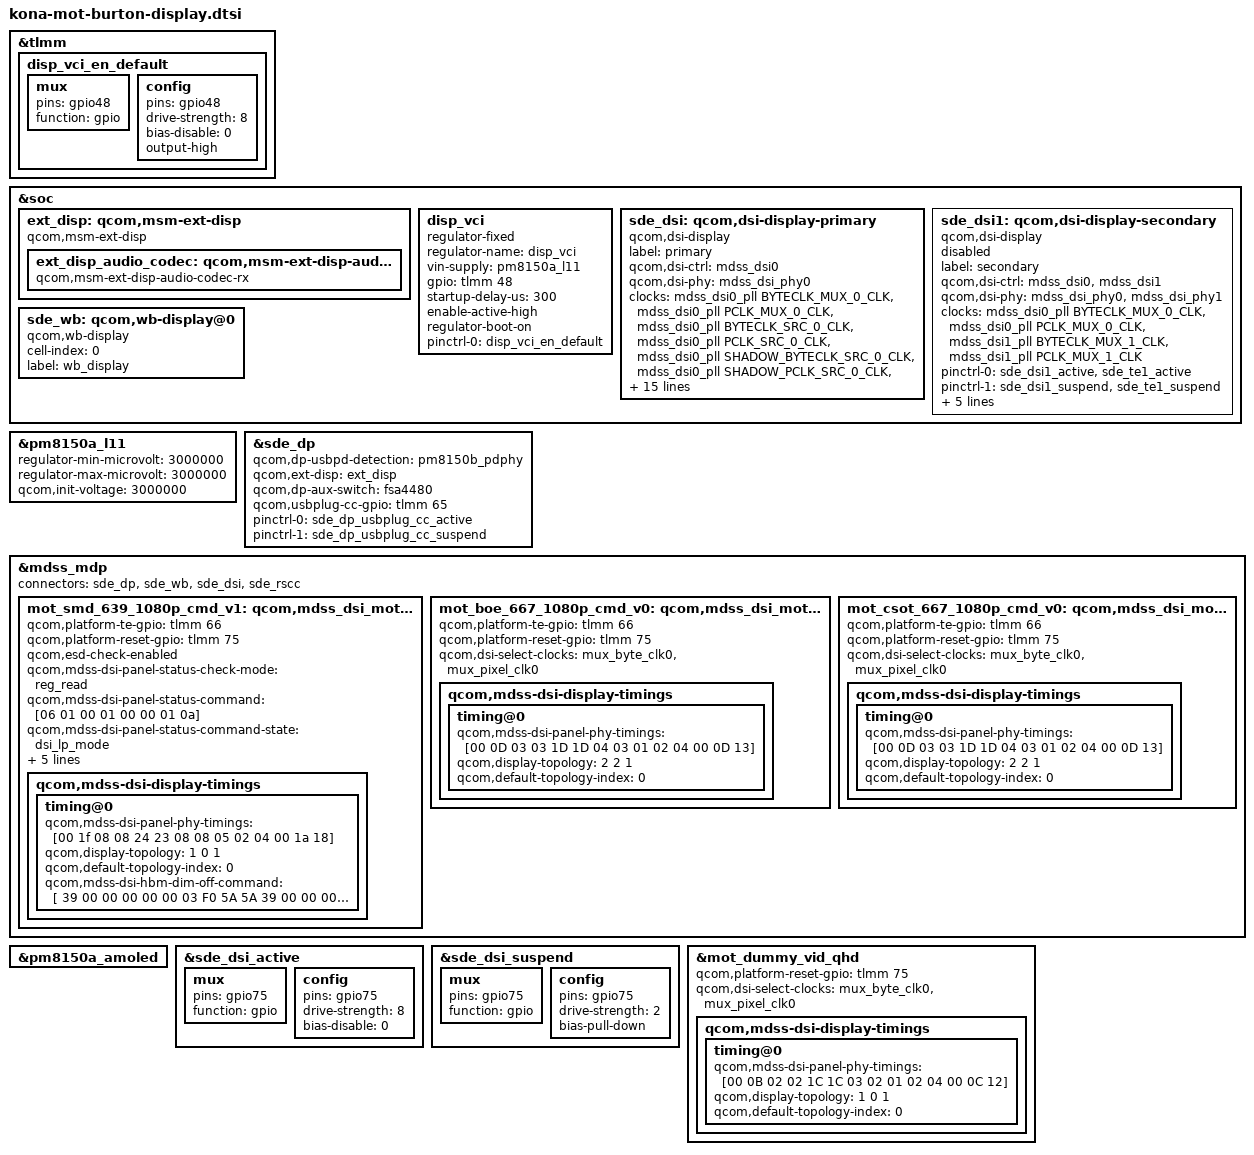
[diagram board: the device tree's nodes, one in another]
#include <dt-bindings/clock/mdss-7nm-pll-clk.h>
#include "dsi-panel-mot-dummy-qhd-video.dtsi"

&tlmm {
	disp_vci_en_default: disp_vci_en_default {
		mux {
			pins = "gpio48";
			function = "gpio";
		};

		config {
			pins = "gpio48";
			drive-strength = <8>;
			bias-disable = <0>;
			output-high;
		};
	};
};

&soc {
	ext_disp: qcom,msm-ext-disp {
		compatible = "qcom,msm-ext-disp";

		ext_disp_audio_codec: qcom,msm-ext-disp-audio-codec-rx {
			compatible = "qcom,msm-ext-disp-audio-codec-rx";
		};
	};


	disp_vci: disp_vci {
		compatible = "regulator-fixed";
		regulator-name = "disp_vci";
		vin-supply = <&pm8150a_l11>;
		gpio = <&tlmm 48 0>;
		startup-delay-us = <300>;
		enable-active-high;
		regulator-boot-on;
		pinctrl-names = "default";
		pinctrl-0 = <&disp_vci_en_default>;
	};

	sde_dsi: qcom,dsi-display-primary {
		compatible = "qcom,dsi-display";
		label = "primary";

		qcom,dsi-ctrl = <&mdss_dsi0>;
		qcom,dsi-phy = <&mdss_dsi_phy0>;


		clocks = <&mdss_dsi0_pll BYTECLK_MUX_0_CLK>,
			<&mdss_dsi0_pll PCLK_MUX_0_CLK>,
			<&mdss_dsi0_pll BYTECLK_SRC_0_CLK>,
			<&mdss_dsi0_pll PCLK_SRC_0_CLK>,
			<&mdss_dsi0_pll SHADOW_BYTECLK_SRC_0_CLK>,
			<&mdss_dsi0_pll SHADOW_PCLK_SRC_0_CLK>,
			<&mdss_dsi1_pll BYTECLK_MUX_1_CLK>,
			<&mdss_dsi1_pll PCLK_MUX_1_CLK>,
			<&mdss_dsi1_pll BYTECLK_SRC_1_CLK>,
			<&mdss_dsi1_pll PCLK_SRC_1_CLK>,
			<&mdss_dsi1_pll SHADOW_BYTECLK_SRC_1_CLK>,
			<&mdss_dsi1_pll SHADOW_PCLK_SRC_1_CLK>;

		clock-names = "mux_byte_clk0", "mux_pixel_clk0",
			"src_byte_clk0", "src_pixel_clk0",
			"shadow_byte_clk0", "shadow_pixel_clk0",
			"mux_byte_clk1", "mux_pixel_clk1",
			"src_byte_clk1", "src_pixel_clk1",
			"shadow_byte_clk1", "shadow_pixel_clk1";

		pinctrl-names = "panel_active", "panel_suspend";
		pinctrl-0 = <&sde_dsi_active &sde_te_active>;
		pinctrl-1 = <&sde_dsi_suspend &sde_te_suspend>;

		qcom,platform-te-gpio = <&tlmm 66 0>;
		qcom,panel-te-source = <0>;

		vddio-supply = <&pm8150_l14>;
		vci-supply = <&disp_vci>;
		qcom,dsi-default-panel = <&mot_boe_667_1080p_cmd_v0>;

		qcom,mdp = <&mdss_mdp>;
	};


	sde_dsi1: qcom,dsi-display-secondary {
		compatible = "qcom,dsi-display";
		label = "secondary";

		qcom,dsi-ctrl = <&mdss_dsi0 &mdss_dsi1>;
		qcom,dsi-phy = <&mdss_dsi_phy0 &mdss_dsi_phy1>;

		clocks = <&mdss_dsi0_pll BYTECLK_MUX_0_CLK>,
			<&mdss_dsi0_pll PCLK_MUX_0_CLK>,
			<&mdss_dsi1_pll BYTECLK_MUX_1_CLK>,
			<&mdss_dsi1_pll PCLK_MUX_1_CLK>;
		clock-names = "mux_byte_clk0", "mux_pixel_clk0",
			"mux_byte_clk1", "mux_pixel_clk1";

		pinctrl-names = "panel_active", "panel_suspend";
		pinctrl-0 = <&sde_dsi1_active &sde_te1_active>;
		pinctrl-1 = <&sde_dsi1_suspend &sde_te1_suspend>;

		qcom,platform-te-gpio = <&tlmm 67 0>;
		qcom,panel-te-source = <1>;

		vddio-supply = <&pm8150_l14>;
		vdd-supply = <&pm8150a_l11>;
/*		avdd-supply = <&display_panel_avdd>; */

		qcom,mdp = <&mdss_mdp>;
	};

	sde_wb: qcom,wb-display@0 {
		compatible = "qcom,wb-display";
		cell-index = <0>;
		label = "wb_display";
	};
};

&pm8150a_l11 {
	regulator-min-microvolt = <3000000>;
	regulator-max-microvolt = <3000000>;
	qcom,init-voltage = <3000000>;
};

&sde_dp {
	qcom,dp-usbpd-detection = <&pm8150b_pdphy>;
	qcom,ext-disp = <&ext_disp>;
	qcom,dp-aux-switch = <&fsa4480>;

	qcom,usbplug-cc-gpio = <&tlmm 65 0>;

	pinctrl-names = "mdss_dp_active", "mdss_dp_sleep";
	pinctrl-0 = <&sde_dp_usbplug_cc_active>;
	pinctrl-1 = <&sde_dp_usbplug_cc_suspend>;
};

&mdss_mdp {
	connectors = <&sde_dp &sde_wb &sde_dsi &sde_rscc>;
	mot_smd_639_1080p_cmd_v1: qcom,mdss_dsi_mot_smd_639_1080p_cmd_v1 {
		#include "dsi-panel-mot-smd-639-1080p-cmd-common.dtsi"
	};

	mot_boe_667_1080p_cmd_v0: qcom,mdss_dsi_mot_boe_667_1080p_cmd_v0 {
		#include "dsi-panel-mot-boe-667-1080p-dsc-cmd-common.dtsi"
	};

	mot_csot_667_1080p_cmd_v0: qcom,mdss_dsi_mot_csot_667_1080p_cmd_v0 {
		#include "dsi-panel-mot-csot-667-1080p-dsc-cmd-common.dtsi"
	};
};

&sde_dsi1 {
	status = "disabled";
};

&pm8150a_amoled {
	status = "ok";
};

&sde_dsi_active {
	mux {
		pins = "gpio75";
		function = "gpio";
	};

	config {
		pins = "gpio75";
		drive-strength = <8>;   /* 8 mA */
		bias-disable = <0>;   /* no pull */
	};
};


&sde_dsi_suspend {
	mux {
		pins = "gpio75";
		function = "gpio";
	};

	config {
		pins = "gpio75";
		drive-strength = <2>;   /* 2 mA */
		bias-pull-down;         /* PULL DOWN */
	};
};

/* PHY TIMINGS REVISION Y */
&mot_smd_639_1080p_cmd_v1 {
/*        qcom,mdss-brightness-max-level = <255>;
*/
        qcom,platform-te-gpio = <&tlmm 66 0>;
        qcom,platform-reset-gpio = <&tlmm 75 0>;

	qcom,esd-check-enabled;
	qcom,mdss-dsi-panel-status-check-mode = "reg_read";
	qcom,mdss-dsi-panel-status-command = [06 01 00 01 00 00 01 0a];
	qcom,mdss-dsi-panel-status-command-state = "dsi_lp_mode";
	qcom,mdss-dsi-panel-status-value = <0x9c>;
	qcom,mdss-dsi-panel-status-read-length = <1>;
	qcom,mdss-dsi-hbm-dim-off;

	qcom,dsi-select-clocks = "mux_byte_clk0", "mux_pixel_clk0";
	qcom,mdss-dsi-display-timings {
		timing@0 {
			qcom,mdss-dsi-panel-phy-timings = [00 1f 08 08 24 23 08
							08 05 02 04 00 1a 18];
			qcom,display-topology = <1 0 1>;
			qcom,default-topology-index = <0>;

			qcom,mdss-dsi-hbm-dim-off-command = [
				39 00 00 00 00 00 03 F0 5A 5A
				39 00 00 00 00 00 03 B7 01 58
				15 01 00 00 00 00 02 B0 07
				15 01 00 00 00 00 02 B7 12
				39 00 00 00 00 00 03 F0 5A 5A];
		};
	};
};

&mot_boe_667_1080p_cmd_v0 {
	qcom,platform-te-gpio = <&tlmm 66 0>;
	qcom,platform-reset-gpio = <&tlmm 75 0>;

	/* disable ESD for bringup
	qcom,esd-check-enabled;
	qcom,mdss-dsi-panel-status-check-mode = "reg_read";
	qcom,mdss-dsi-panel-status-command = [06 01 00 01 00 00 01 0a];
	qcom,mdss-dsi-panel-status-command-state = "dsi_lp_mode";
	qcom,mdss-dsi-panel-status-value = <0x9c>;
	qcom,mdss-dsi-panel-status-read-length = <1>;
	qcom,mdss-dsi-hbm-dim-off;
	*/

	qcom,dsi-select-clocks = "mux_byte_clk0", "mux_pixel_clk0";
	qcom,mdss-dsi-display-timings {
		timing@0 {
			/* Phy 4; w=2880 h=2340; 10bits 60hz; 3.75x dsc */
			qcom,mdss-dsi-panel-phy-timings = [00 0D 03 03 1D 1D 04
							03 01 02 04 00 0D 13];
			qcom,display-topology = <2 2 1>;
			qcom,default-topology-index = <0>;
		};
	};
};

&mot_csot_667_1080p_cmd_v0 {
	qcom,platform-te-gpio = <&tlmm 66 0>;
	qcom,platform-reset-gpio = <&tlmm 75 0>;

	/* disable ESD for bringup
	qcom,esd-check-enabled;
	qcom,mdss-dsi-panel-status-check-mode = "reg_read";
	qcom,mdss-dsi-panel-status-command = [06 01 00 01 00 00 01 0a];
	qcom,mdss-dsi-panel-status-command-state = "dsi_lp_mode";
	qcom,mdss-dsi-panel-status-value = <0x9c>;
	qcom,mdss-dsi-panel-status-read-length = <1>;
	qcom,mdss-dsi-hbm-dim-off;
	*/

	qcom,dsi-select-clocks = "mux_byte_clk0", "mux_pixel_clk0";
	qcom,mdss-dsi-display-timings {
		timing@0 {
			/* Phy 4; w=2880 h=2340; 10bits 60hz; 3.75x dsc */
			qcom,mdss-dsi-panel-phy-timings = [00 0D 03 03 1D 1D 04
							03 01 02 04 00 0D 13];
			qcom,display-topology = <2 2 1>;
			qcom,default-topology-index = <0>;
		};
	};
};

&mot_dummy_vid_qhd {
	qcom,platform-reset-gpio = <&tlmm 75 0>;

	qcom,dsi-select-clocks = "mux_byte_clk0", "mux_pixel_clk0";
	qcom,mdss-dsi-display-timings {
		timing@0 {
			qcom,mdss-dsi-panel-phy-timings = [00 0B 02 02 1C 1C 03
							02 01 02 04 00 0C 12];
			qcom,display-topology = <1 0 1>;
			qcom,default-topology-index = <0>;
		};
	};
};
